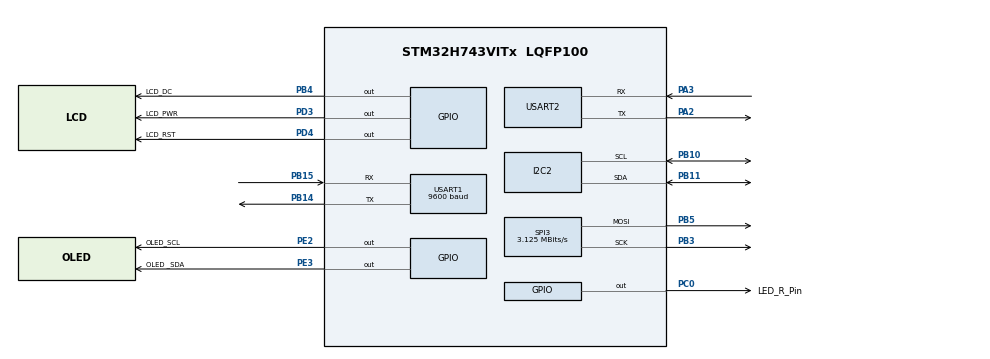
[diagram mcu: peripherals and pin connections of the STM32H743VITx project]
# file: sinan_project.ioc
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Dma.Request0=USART2_RX
Dma.USART2_RX.0.Direction=DMA_PERIPH_TO_MEMORY
Dma.USART2_RX.0.EventEnable=DISABLE
Dma.USART2_RX.0.FIFOMode=DMA_FIFOMODE_DISABLE
Dma.USART2_RX.0.Instance=DMA1_Stream0
Dma.USART2_RX.0.MemDataAlignment=DMA_MDATAALIGN_BYTE
Dma.USART2_RX.0.MemInc=DMA_MINC_ENABLE
Dma.USART2_RX.0.Mode=DMA_NORMAL
Dma.USART2_RX.0.PeriphDataAlignment=DMA_PDATAALIGN_BYTE
Dma.USART2_RX.0.PeriphInc=DMA_PINC_DISABLE
Dma.USART2_RX.0.Polarity=HAL_DMAMUX_REQ_GEN_RISING
Dma.USART2_RX.0.Priority=DMA_PRIORITY_LOW
Dma.USART2_RX.0.RequestNumber=1
Dma.USART2_RX.0.SignalID=NONE
Dma.USART2_RX.0.SyncEnable=DISABLE
Dma.USART2_RX.0.SyncPolarity=HAL_DMAMUX_SYNC_NO_EVENT
Dma.USART2_RX.0.SyncRequestNumber=1
Dma.USART2_RX.0.SyncSignalID=NONE
I2C2.Timing=0x10C0ECFF
Mcu.Family=STM32H7
Mcu.Name=STM32H743VITx
Mcu.Package=LQFP100
NVIC.DMA1_Stream0_IRQn=true\:0\:0\:false\:false\:true\:false\:true\:true
NVIC.PriorityGroup=NVIC_PRIORITYGROUP_4
NVIC.TIM2_IRQn=true\:1\:0\:true\:false\:true\:true\:true\:true
NVIC.TIM3_IRQn=true\:3\:0\:true\:false\:true\:true\:true\:true
NVIC.USART1_IRQn=true\:0\:0\:false\:false\:true\:true\:true\:true
NVIC.USART2_IRQn=true\:0\:0\:false\:false\:true\:true\:true\:true
PA13\ (JTMS/SWDIO).Mode=Serial_Wire
PA13\ (JTMS/SWDIO).Signal=DEBUG_JTMS-SWDIO
PA14\ (JTCK/SWCLK).Mode=Serial_Wire
PA14\ (JTCK/SWCLK).Signal=DEBUG_JTCK-SWCLK
PA2.Mode=Asynchronous
PA2.Signal=USART2_TX
PA3.Mode=Asynchronous
PA3.Signal=USART2_RX
PB10.Mode=I2C
PB10.Signal=I2C2_SCL
PB11.Mode=I2C
PB11.Signal=I2C2_SDA
PB14.Mode=Asynchronous
PB14.Signal=USART1_TX
PB15.Mode=Asynchronous
PB15.Signal=USART1_RX
PB3\ (JTDO/TRACESWO).Mode=TX_Only_Simplex_Unidirect_Master
PB3\ (JTDO/TRACESWO).Signal=SPI3_SCK
PB4\ (NJTRST).GPIO_Label=LCD_DC
PB4\ (NJTRST).Signal=GPIO_Output
PB5.Mode=TX_Only_Simplex_Unidirect_Master
PB5.Signal=SPI3_MOSI
PC0.GPIO_Label=LED_R_Pin
PC0.GPIO_ModeDefaultOutputPP=GPIO_MODE_OUTPUT_PP
PC0.GPIO_PuPd=GPIO_NOPULL
PC0.GPIO_Speed=GPIO_SPEED_FREQ_LOW
PC0.Signal=GPIO_Output
PD3.GPIO_Label=LCD_PWR
PD3.Signal=GPIO_Output
PD4.GPIO_Label=LCD_RST
PD4.Signal=GPIO_Output
PE2.GPIO_Label=OLED_SCL
PE2.GPIO_Speed=GPIO_SPEED_FREQ_VERY_HIGH
PE2.Signal=GPIO_Output
PE3.GPIO_Label=OLED _SDA
PE3.GPIO_Speed=GPIO_SPEED_FREQ_VERY_HIGH
PE3.Signal=GPIO_Output
PH0-OSC_IN\ (PH0).Mode=HSE-External-Oscillator
PH0-OSC_IN\ (PH0).Signal=RCC_OSC_IN
PH1-OSC_OUT\ (PH1).Mode=HSE-External-Oscillator
PH1-OSC_OUT\ (PH1).Signal=RCC_OSC_OUT
ProjectManager.HeapSize=0x200
ProjectManager.StackSize=0x400
ProjectManager.TargetToolchain=MDK-ARM V5.32
RCC.ADCFreq_Value=200000000
RCC.APB1Freq_Value=100000000
RCC.APB2Freq_Value=100000000
RCC.APB3Freq_Value=100000000
RCC.APB4Freq_Value=100000000
RCC.CortexFreq_Value=400000000
RCC.D1PPRE=RCC_APB3_DIV2
RCC.D2PPRE1=RCC_APB1_DIV2
RCC.D2PPRE2=RCC_APB2_DIV2
RCC.D3PPRE=RCC_APB4_DIV2
RCC.DIVM1=2
RCC.DIVM2=16
RCC.DIVN1=64
RCC.DIVN2=256
RCC.HCLKFreq_Value=200000000
RCC.HPRE=RCC_HCLK_DIV2
RCC.PLLFRACN=0
RCC.PLLSourceVirtual=RCC_PLLSOURCE_HSE
RCC.SPI123CLockSelection=RCC_SPI123CLKSOURCE_PLL2
RCC.SYSCLKFreq_VALUE=400000000
RCC.SYSCLKSource=RCC_SYSCLKSOURCE_PLLCLK
RCC.Tim1Mul=2
RCC.USBFreq_Value=400000000
SPI3.BaudRatePrescaler=SPI_BAUDRATEPRESCALER_64
SPI3.CLKPhase=SPI_PHASE_2EDGE
SPI3.CLKPolarity=SPI_POLARITY_HIGH
SPI3.CalculateBaudRate=3.125 MBits/s
SPI3.DataSize=SPI_DATASIZE_8BIT
SPI3.Direction=SPI_DIRECTION_2LINES_TXONLY
SPI3.Mode=SPI_MODE_MASTER
SPI3.VirtualType=VM_MASTER
TIM2.Period=2000
TIM2.Prescaler=1000
TIM3.Period=4000
TIM3.Prescaler=1000
USART1.BaudRate=9600
USART1.VirtualMode-Asynchronous=VM_ASYNC
USART2.VirtualMode-Asynchronous=VM_ASYNC
VP_TIM2_VS_ClockSourceINT.Mode=Internal
VP_TIM3_VS_ClockSourceINT.Mode=Internal
board=custom

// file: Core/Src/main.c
/* USER CODE BEGIN Header */
/**
  ******************************************************************************
  * @file           : main.c
  * @brief          : Main program body
  ******************************************************************************
  * @attention
  *
  * Copyright (c) 2025 STMicroelectronics.
  * All rights reserved.
  *
  * This software is licensed under terms that can be found in the LICENSE file
  * in the root directory of this software component.
  * If no LICENSE file comes with this software, it is provided AS-IS.
  *
  ******************************************************************************
  */
/* USER CODE END Header */
#include "main.h"
#include "dma.h"
#include "i2c.h"
#include "spi.h"
#include "tim.h"
#include "usart.h"
#include "gpio.h"

/* USER CODE BEGIN Includes */
#include "UWB.h"
#include "lcd.h"

/* USER CODE END Includes */

void SystemClock_Config(void);

int main(void)
{

  /* MCU Configuration--------------------------------------------------------*/

  /* Reset of all peripherals, Initializes the Flash interface and the Systick. */
  HAL_Init();

  /* Configure the system clock */
  SystemClock_Config();

  /* Initialize all configured peripherals */
  MX_GPIO_Init();
  MX_DMA_Init();
  MX_SPI3_Init();
  MX_I2C2_Init();
  MX_TIM2_Init();
  MX_TIM3_Init();
	MX_USART1_UART_Init();
  MX_USART2_UART_Init();
  /* USER CODE BEGIN 2 */
//	UWB_Init(&UWB);
	HAL_UARTEx_ReceiveToIdle_DMA(&huart2,UWB.Modbus_buffer,sizeof(UWB.Modbus_buffer));
	IMU_Init(&IMU931);
	HAL_TIM_Base_Start_IT(&htim2);
	HAL_TIM_Base_Start_IT(&htim3);
  OLED_Init();
  INS_Init();
  LCD_Init();

  /* USER CODE END 2 */

  /* Infinite loop */
  while (1)
  {

  }
}

void SystemClock_Config(void)
{
  RCC_OscInitTypeDef RCC_OscInitStruct = {0};
  RCC_ClkInitTypeDef RCC_ClkInitStruct = {0};

  /** Supply configuration update enable
  */
  HAL_PWREx_ConfigSupply(PWR_LDO_SUPPLY);

  /** Configure the main internal regulator output voltage
  */
  __HAL_PWR_VOLTAGESCALING_CONFIG(PWR_REGULATOR_VOLTAGE_SCALE1);

  while(!__HAL_PWR_GET_FLAG(PWR_FLAG_VOSRDY)) {}

  /** Initializes the RCC Oscillators according to the specified parameters
  * in the RCC_OscInitTypeDef structure.
  */
  RCC_OscInitStruct.OscillatorType = RCC_OSCILLATORTYPE_HSE;
  RCC_OscInitStruct.HSEState = RCC_HSE_ON;
  RCC_OscInitStruct.PLL.PLLState = RCC_PLL_ON;
  RCC_OscInitStruct.PLL.PLLSource = RCC_PLLSOURCE_HSE;
  RCC_OscInitStruct.PLL.PLLM = 2;
  RCC_OscInitStruct.PLL.PLLN = 64;
  RCC_OscInitStruct.PLL.PLLP = 2;
  RCC_OscInitStruct.PLL.PLLQ = 2;
  RCC_OscInitStruct.PLL.PLLR = 2;
  RCC_OscInitStruct.PLL.PLLRGE = RCC_PLL1VCIRANGE_3;
  RCC_OscInitStruct.PLL.PLLVCOSEL = RCC_PLL1VCOWIDE;
  RCC_OscInitStruct.PLL.PLLFRACN = 0;
  if (HAL_RCC_OscConfig(&RCC_OscInitStruct) != HAL_OK)
  {
    Error_Handler();
  }

  /** Initializes the CPU, AHB and APB buses clocks
  */
  RCC_ClkInitStruct.ClockType = RCC_CLOCKTYPE_HCLK|RCC_CLOCKTYPE_SYSCLK
                              |RCC_CLOCKTYPE_PCLK1|RCC_CLOCKTYPE_PCLK2
                              |RCC_CLOCKTYPE_D3PCLK1|RCC_CLOCKTYPE_D1PCLK1;
  RCC_ClkInitStruct.SYSCLKSource = RCC_SYSCLKSOURCE_PLLCLK;
  RCC_ClkInitStruct.SYSCLKDivider = RCC_SYSCLK_DIV1;
  RCC_ClkInitStruct.AHBCLKDivider = RCC_HCLK_DIV2;
  RCC_ClkInitStruct.APB3CLKDivider = RCC_APB3_DIV2;
  RCC_ClkInitStruct.APB1CLKDivider = RCC_APB1_DIV2;
  RCC_ClkInitStruct.APB2CLKDivider = RCC_APB2_DIV2;
  RCC_ClkInitStruct.APB4CLKDivider = RCC_APB4_DIV2;

  if (HAL_RCC_ClockConfig(&RCC_ClkInitStruct, FLASH_LATENCY_2) != HAL_OK)
  {
    Error_Handler();
  }
}

/* USER CODE BEGIN 4 */

void HAL_TIM_PeriodElapsedCallback(TIM_HandleTypeDef *htim)
{
	if(htim->Instance == TIM2)
	{
		// IMU_hook(&IMU931);
	}
	else if(htim->Instance == TIM3)
	{
		// static uint8_t flag;
		// flag++;
		// if(flag > 100)
		// INS_region_cal();
	}
}

/* USER CODE END 4 */

void Error_Handler(void)
{
  __disable_irq();
  while (1)
  {
  }
}
